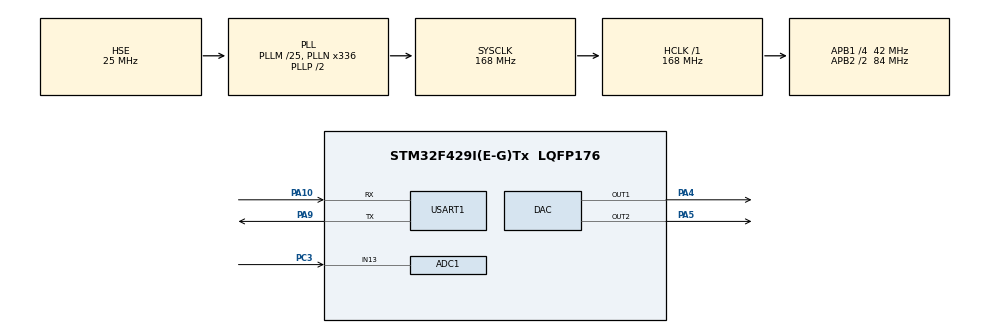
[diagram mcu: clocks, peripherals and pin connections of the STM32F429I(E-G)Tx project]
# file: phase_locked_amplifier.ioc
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ADC1.Channel-5\#ChannelRegularConversion=ADC_CHANNEL_13
ADC1.DMAContinuousRequests=ENABLE
ADC1.ExternalTrigConv=ADC_EXTERNALTRIGCONV_T2_CC2
ADC1.ExternalTrigConvEdge=ADC_EXTERNALTRIGCONVEDGE_RISING
ADC1.NbrOfConversionFlag=1
ADC1.Rank-5\#ChannelRegularConversion=1
ADC1.SamplingTime-5\#ChannelRegularConversion=ADC_SAMPLETIME_3CYCLES
ADC1.master=1
DAC.DAC_Trigger=DAC_TRIGGER_T2_TRGO
DAC.DAC_Trigger2=DAC_TRIGGER_T2_TRGO
Dma.ADC1.0.Direction=DMA_PERIPH_TO_MEMORY
Dma.ADC1.0.FIFOMode=DMA_FIFOMODE_DISABLE
Dma.ADC1.0.Instance=DMA2_Stream0
Dma.ADC1.0.MemDataAlignment=DMA_MDATAALIGN_HALFWORD
Dma.ADC1.0.MemInc=DMA_MINC_ENABLE
Dma.ADC1.0.Mode=DMA_CIRCULAR
Dma.ADC1.0.PeriphDataAlignment=DMA_PDATAALIGN_HALFWORD
Dma.ADC1.0.PeriphInc=DMA_PINC_DISABLE
Dma.ADC1.0.Priority=DMA_PRIORITY_LOW
Dma.DAC1.1.Direction=DMA_MEMORY_TO_PERIPH
Dma.DAC1.1.FIFOMode=DMA_FIFOMODE_DISABLE
Dma.DAC1.1.Instance=DMA1_Stream5
Dma.DAC1.1.MemDataAlignment=DMA_MDATAALIGN_HALFWORD
Dma.DAC1.1.MemInc=DMA_MINC_ENABLE
Dma.DAC1.1.Mode=DMA_CIRCULAR
Dma.DAC1.1.PeriphDataAlignment=DMA_PDATAALIGN_HALFWORD
Dma.DAC1.1.PeriphInc=DMA_PINC_DISABLE
Dma.DAC1.1.Priority=DMA_PRIORITY_LOW
Dma.DAC2.2.Direction=DMA_MEMORY_TO_PERIPH
Dma.DAC2.2.FIFOMode=DMA_FIFOMODE_DISABLE
Dma.DAC2.2.Instance=DMA1_Stream6
Dma.DAC2.2.MemDataAlignment=DMA_MDATAALIGN_HALFWORD
Dma.DAC2.2.MemInc=DMA_MINC_ENABLE
Dma.DAC2.2.Mode=DMA_CIRCULAR
Dma.DAC2.2.PeriphDataAlignment=DMA_PDATAALIGN_HALFWORD
Dma.DAC2.2.PeriphInc=DMA_PINC_DISABLE
Dma.DAC2.2.Priority=DMA_PRIORITY_LOW
Dma.Request0=ADC1
Dma.Request1=DAC1
Dma.Request2=DAC2
Mcu.Family=STM32F4
Mcu.Name=STM32F429I(E-G)Tx
Mcu.Package=LQFP176
NVIC.ADC_IRQn=true\:0\:0\:false\:false\:true\:true\:true\:true
NVIC.DMA1_Stream5_IRQn=true\:0\:0\:false\:false\:true\:false\:true\:true
NVIC.DMA1_Stream6_IRQn=true\:0\:0\:false\:false\:true\:false\:true\:true
NVIC.DMA2_Stream0_IRQn=true\:0\:0\:false\:false\:true\:false\:true\:true
NVIC.PriorityGroup=NVIC_PRIORITYGROUP_4
NVIC.USART1_IRQn=true\:0\:0\:false\:false\:true\:true\:true\:true
PA10.Mode=Asynchronous
PA10.Signal=USART1_RX
PA4.Signal=COMP_DAC1_group
PA5.Signal=COMP_DAC2_group
PA9.Mode=Asynchronous
PA9.Signal=USART1_TX
PC14/OSC32_IN.Mode=LSE-External-Oscillator
PC14/OSC32_IN.Signal=RCC_OSC32_IN
PC15/OSC32_OUT.Mode=LSE-External-Oscillator
PC15/OSC32_OUT.Signal=RCC_OSC32_OUT
PC3.Signal=ADCx_IN13
PH0/OSC_IN.Mode=HSE-External-Oscillator
PH0/OSC_IN.Signal=RCC_OSC_IN
PH1/OSC_OUT.Mode=HSE-External-Oscillator
PH1/OSC_OUT.Signal=RCC_OSC_OUT
ProjectManager.HeapSize=0x200
ProjectManager.StackSize=0x400
ProjectManager.TargetToolchain=MDK-ARM V5.32
RCC.48MHZClocksFreq_Value=84000000
RCC.AHBFreq_Value=168000000
RCC.APB1CLKDivider=RCC_HCLK_DIV4
RCC.APB1Freq_Value=42000000
RCC.APB1TimFreq_Value=84000000
RCC.APB2CLKDivider=RCC_HCLK_DIV2
RCC.APB2Freq_Value=84000000
RCC.APB2TimFreq_Value=168000000
RCC.CortexFreq_Value=168000000
RCC.HCLKFreq_Value=168000000
RCC.HSE_VALUE=25000000
RCC.HSI_VALUE=16000000
RCC.PLLM=25
RCC.PLLN=336
RCC.PLLSourceVirtual=RCC_PLLSOURCE_HSE
RCC.SYSCLKFreq_VALUE=168000000
RCC.SYSCLKSource=RCC_SYSCLKSOURCE_PLLCLK
RCC.VCOOutputFreq_Value=336000000
SH.ADCx_IN13.0=ADC1_IN13,IN13
SH.COMP_DAC1_group.0=DAC_OUT1,DAC_OUT1
SH.COMP_DAC2_group.0=DAC_OUT2,DAC_OUT2
TIM2.Channel-PWM\ Generation2\ No\ Output=TIM_CHANNEL_2
TIM2.OCMode_PWM-PWM\ Generation2\ No\ Output=TIM_OCMODE_PWM1
TIM2.Period=10-1
TIM2.Prescaler=84-1
TIM2.Pulse-PWM\ Generation2\ No\ Output=25000-1
TIM2.TIM_MasterOutputTrigger=TIM_TRGO_UPDATE
USART1.VirtualMode=VM_ASYNC
VP_TIM2_VS_ClockSourceINT.Mode=Internal
VP_TIM2_VS_no_output2.Mode=PWM Generation2 No Output
board=custom

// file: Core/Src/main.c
/* USER CODE BEGIN Header */
/**
  ******************************************************************************
  * @file           : main.c
  * @brief          : Main program body
  ******************************************************************************
  * @attention
  *
  * Copyright (c) 2025 STMicroelectronics.
  * All rights reserved.
  *
  * This software is licensed under terms that can be found in the LICENSE file
  * in the root directory of this software component.
  * If no LICENSE file comes with this software, it is provided AS-IS.
  *
  ******************************************************************************
  */
/* USER CODE END Header */
#include "main.h"
#include "adc.h"
#include "dac.h"
#include "dma.h"
#include "tim.h"
#include "usart.h"
#include "gpio.h"

/* USER CODE BEGIN Includes */
#include "stdio.h"
/* USER CODE END Includes */

/* USER CODE BEGIN PD */
#define ADC_BUFFER_LENGTH 100

uint16_t adc_buffer[ADC_BUFFER_LENGTH] ;
float adc_voltage;
/* USER CODE END PD */

void SystemClock_Config(void);

int main(void)
{

  /* MCU Configuration--------------------------------------------------------*/

  /* Reset of all peripherals, Initializes the Flash interface and the Systick. */
  HAL_Init();

  /* Configure the system clock */
  SystemClock_Config();

  /* Initialize all configured peripherals */
  MX_GPIO_Init();
  MX_DMA_Init();
  MX_ADC1_Init();
  MX_USART1_UART_Init();
  MX_TIM2_Init();
  MX_DAC_Init();
  /* USER CODE BEGIN 2 */
	printf("Phase Locked Amplifier.");
	//开启ADC+DMA、DAC+DMA、PWM
	HAL_ADC_Start_DMA(&hadc1,(uint32_t *)&adc_buffer,ADC_BUFFER_LENGTH);
	HAL_DAC_Start_DMA(&hdac, DAC_CHANNEL_1, (uint32_t *)adc_buffer, sizeof(adc_buffer), DAC_ALIGN_8B_R);
	HAL_TIM_PWM_Start(&htim2, TIM_CHANNEL_2);
  /* USER CODE END 2 */

  /* Infinite loop */
  while (1)
  {

  }
}

void SystemClock_Config(void)
{
  RCC_OscInitTypeDef RCC_OscInitStruct = {0};
  RCC_ClkInitTypeDef RCC_ClkInitStruct = {0};

  /** Configure the main internal regulator output voltage
  */
  __HAL_RCC_PWR_CLK_ENABLE();
  __HAL_PWR_VOLTAGESCALING_CONFIG(PWR_REGULATOR_VOLTAGE_SCALE1);

  /** Initializes the RCC Oscillators according to the specified parameters
  * in the RCC_OscInitTypeDef structure.
  */
  RCC_OscInitStruct.OscillatorType = RCC_OSCILLATORTYPE_HSE;
  RCC_OscInitStruct.HSEState = RCC_HSE_ON;
  RCC_OscInitStruct.PLL.PLLState = RCC_PLL_ON;
  RCC_OscInitStruct.PLL.PLLSource = RCC_PLLSOURCE_HSE;
  RCC_OscInitStruct.PLL.PLLM = 25;
  RCC_OscInitStruct.PLL.PLLN = 336;
  RCC_OscInitStruct.PLL.PLLP = RCC_PLLP_DIV2;
  RCC_OscInitStruct.PLL.PLLQ = 4;
  if (HAL_RCC_OscConfig(&RCC_OscInitStruct) != HAL_OK)
  {
    Error_Handler();
  }

  /** Initializes the CPU, AHB and APB buses clocks
  */
  RCC_ClkInitStruct.ClockType = RCC_CLOCKTYPE_HCLK|RCC_CLOCKTYPE_SYSCLK
                              |RCC_CLOCKTYPE_PCLK1|RCC_CLOCKTYPE_PCLK2;
  RCC_ClkInitStruct.SYSCLKSource = RCC_SYSCLKSOURCE_PLLCLK;
  RCC_ClkInitStruct.AHBCLKDivider = RCC_SYSCLK_DIV1;
  RCC_ClkInitStruct.APB1CLKDivider = RCC_HCLK_DIV4;
  RCC_ClkInitStruct.APB2CLKDivider = RCC_HCLK_DIV2;

  if (HAL_RCC_ClockConfig(&RCC_ClkInitStruct, FLASH_LATENCY_5) != HAL_OK)
  {
    Error_Handler();
  }
}

/* USER CODE BEGIN 4 */
//ADC完成一次DMA采样后回调
void HAL_ADC_ConvCpltCallback(ADC_HandleTypeDef* hadc)
{
	if (hadc->Instance == ADC1)
	{
		/*
		 printf("DMA 采样完成，数据如下：\r\n");
    for (int i = 0; i < ADC_BUFFER_LENGTH; i++)
    {
			adc_voltage = (adc_buffer[i]*3.3)/4095;
     printf("ADC  %d  %f\r\n",adc_buffer[i],adc_voltage);
    }
    printf("\r\n");
*/
	}
}
void HAL_DAC_ConvCpltCallbackCh1(DAC_HandleTypeDef* hdac)
{
    printf("DAC DMA 传输完成\r\n");
}

/* USER CODE END 4 */

void Error_Handler(void)
{
  __disable_irq();
  while (1)
  {
  }
}
